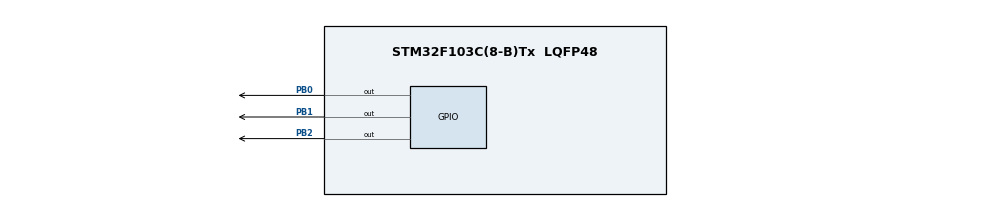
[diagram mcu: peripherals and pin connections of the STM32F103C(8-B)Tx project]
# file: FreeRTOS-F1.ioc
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FREERTOS.Tasks01=defaultTask,0,128,StartDefaultTask,Default;myTask01,-3,128,StartTask01,Default;myTask02,-3,128,StartTask02,Default
Mcu.Family=STM32F1
Mcu.Name=STM32F103C(8-B)Tx
Mcu.Package=LQFP48
NVIC.PriorityGroup=NVIC_PRIORITYGROUP_4
NVIC.TIM4_IRQn=true\:0\:0\:false\:false\:true\:false
NVIC.TimeBase=TIM4_IRQn
NVIC.TimeBaseIP=TIM4
PB0.Signal=GPIO_Output
PB1.Signal=GPIO_Output
PB2.Signal=GPIO_Output
ProjectManager.HeapSize=0x200
ProjectManager.StackSize=0x400
ProjectManager.TargetToolchain=MDK-ARM V4
RCC.APB1Freq_Value=8000000
RCC.APB2Freq_Value=8000000
VP_FREERTOS_VS_ENABLE.Mode=Enabled
VP_SYS_VS_ND.Mode=No_Debug
VP_SYS_VS_tim4.Mode=TIM4
board=FreeRTOS-F1

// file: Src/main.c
/**
  ******************************************************************************
  * File Name          : main.c
  * Description        : Main program body
  ******************************************************************************
  *
  * COPYRIGHT(c) 2016 STMicroelectronics
  *
  * Redistribution and use in source and binary forms, with or without modification,
  * are permitted provided that the following conditions are met:
  *   1. Redistributions of source code must retain the above copyright notice,
  *      this list of conditions and the following disclaimer.
  *   2. Redistributions in binary form must reproduce the above copyright notice,
  *      this list of conditions and the following disclaimer in the documentation
  *      and/or other materials provided with the distribution.
  *   3. Neither the name of STMicroelectronics nor the names of its contributors
  *      may be used to endorse or promote products derived from this software
  *      without specific prior written permission.
  *
  * THIS SOFTWARE IS PROVIDED BY THE COPYRIGHT HOLDERS AND CONTRIBUTORS "AS IS"
  * AND ANY EXPRESS OR IMPLIED WARRANTIES, INCLUDING, BUT NOT LIMITED TO, THE
  * IMPLIED WARRANTIES OF MERCHANTABILITY AND FITNESS FOR A PARTICULAR PURPOSE ARE
  * DISCLAIMED. IN NO EVENT SHALL THE COPYRIGHT HOLDER OR CONTRIBUTORS BE LIABLE
  * FOR ANY DIRECT, INDIRECT, INCIDENTAL, SPECIAL, EXEMPLARY, OR CONSEQUENTIAL
  * DAMAGES (INCLUDING, BUT NOT LIMITED TO, PROCUREMENT OF SUBSTITUTE GOODS OR
  * SERVICES; LOSS OF USE, DATA, OR PROFITS; OR BUSINESS INTERRUPTION) HOWEVER
  * CAUSED AND ON ANY THEORY OF LIABILITY, WHETHER IN CONTRACT, STRICT LIABILITY,
  * OR TORT (INCLUDING NEGLIGENCE OR OTHERWISE) ARISING IN ANY WAY OUT OF THE USE
  * OF THIS SOFTWARE, EVEN IF ADVISED OF THE POSSIBILITY OF SUCH DAMAGE.
  *
  ******************************************************************************
  */
#include "stm32f1xx_hal.h"
#include "cmsis_os.h"

osThreadId defaultTaskHandle;
osThreadId myTask01Handle;
osThreadId myTask02Handle;

/* USER CODE BEGIN PV */
/* Private variables ---------------------------------------------------------*/

/* USER CODE END PV */

void SystemClock_Config(void);
void Error_Handler(void);
static void MX_GPIO_Init(void);
void StartDefaultTask(void const * argument);
void StartTask01(void const * argument);
void StartTask02(void const * argument);

/* USER CODE BEGIN PFP */
/* Private function prototypes -----------------------------------------------*/

/* USER CODE END PFP */

int main(void)
{

  /* MCU Configuration----------------------------------------------------------*/

  /* Reset of all peripherals, Initializes the Flash interface and the Systick. */
  HAL_Init();

  /* Configure the system clock */
  SystemClock_Config();

  /* Initialize all configured peripherals */
  MX_GPIO_Init();

  /* Create the thread(s) */
  /* definition and creation of defaultTask */
  osThreadDef(defaultTask, StartDefaultTask, osPriorityNormal, 0, 128);
  defaultTaskHandle = osThreadCreate(osThread(defaultTask), NULL);

  /* definition and creation of myTask01 */
  osThreadDef(myTask01, StartTask01, osPriorityIdle, 0, 128);
  myTask01Handle = osThreadCreate(osThread(myTask01), NULL);

  /* definition and creation of myTask02 */
  osThreadDef(myTask02, StartTask02, osPriorityIdle, 0, 128);
  myTask02Handle = osThreadCreate(osThread(myTask02), NULL);

  /* Start scheduler */
  osKernelStart();

  /* We should never get here as control is now taken by the scheduler */

  /* Infinite loop */
  while (1)
  {

  }

}

/** System Clock Configuration
*/
void SystemClock_Config(void)
{

  RCC_OscInitTypeDef RCC_OscInitStruct;
  RCC_ClkInitTypeDef RCC_ClkInitStruct;

  RCC_OscInitStruct.OscillatorType = RCC_OSCILLATORTYPE_HSI;
  RCC_OscInitStruct.HSIState = RCC_HSI_ON;
  RCC_OscInitStruct.HSICalibrationValue = 16;
  RCC_OscInitStruct.PLL.PLLState = RCC_PLL_NONE;
  if (HAL_RCC_OscConfig(&RCC_OscInitStruct) != HAL_OK)
  {
    Error_Handler();
  }

  RCC_ClkInitStruct.ClockType = RCC_CLOCKTYPE_HCLK|RCC_CLOCKTYPE_SYSCLK
                              |RCC_CLOCKTYPE_PCLK1|RCC_CLOCKTYPE_PCLK2;
  RCC_ClkInitStruct.SYSCLKSource = RCC_SYSCLKSOURCE_HSI;
  RCC_ClkInitStruct.AHBCLKDivider = RCC_SYSCLK_DIV1;
  RCC_ClkInitStruct.APB1CLKDivider = RCC_HCLK_DIV1;
  RCC_ClkInitStruct.APB2CLKDivider = RCC_HCLK_DIV1;
  if (HAL_RCC_ClockConfig(&RCC_ClkInitStruct, FLASH_LATENCY_0) != HAL_OK)
  {
    Error_Handler();
  }

  HAL_SYSTICK_Config(HAL_RCC_GetHCLKFreq()/1000);

  HAL_SYSTICK_CLKSourceConfig(SYSTICK_CLKSOURCE_HCLK);

  /* SysTick_IRQn interrupt configuration */
  HAL_NVIC_SetPriority(SysTick_IRQn, 15, 0);
}

/** Configure pins as
        * Analog
        * Input
        * Output
        * EVENT_OUT
        * EXTI
        * Free pins are configured automatically as Analog (this feature is enabled through
        * the Code Generation settings)
*/
static void MX_GPIO_Init(void)
{

  GPIO_InitTypeDef GPIO_InitStruct;

  /* GPIO Ports Clock Enable */
  __HAL_RCC_GPIOC_CLK_ENABLE();
  __HAL_RCC_GPIOD_CLK_ENABLE();
  __HAL_RCC_GPIOA_CLK_ENABLE();
  __HAL_RCC_GPIOB_CLK_ENABLE();

  /*Configure GPIO pins : PC13 PC14 PC15 */
  GPIO_InitStruct.Pin = GPIO_PIN_13|GPIO_PIN_14|GPIO_PIN_15;
  GPIO_InitStruct.Mode = GPIO_MODE_ANALOG;
  HAL_GPIO_Init(GPIOC, &GPIO_InitStruct);

  /*Configure GPIO pins : PD0 PD1 */
  GPIO_InitStruct.Pin = GPIO_PIN_0|GPIO_PIN_1;
  GPIO_InitStruct.Mode = GPIO_MODE_ANALOG;
  HAL_GPIO_Init(GPIOD, &GPIO_InitStruct);

  /*Configure GPIO pins : PA0 PA1 PA2 PA3
                           PA4 PA5 PA6 PA7
                           PA8 PA9 PA10 PA11
                           PA12 PA13 PA14 PA15 */
  GPIO_InitStruct.Pin = GPIO_PIN_0|GPIO_PIN_1|GPIO_PIN_2|GPIO_PIN_3
                          |GPIO_PIN_4|GPIO_PIN_5|GPIO_PIN_6|GPIO_PIN_7
                          |GPIO_PIN_8|GPIO_PIN_9|GPIO_PIN_10|GPIO_PIN_11
                          |GPIO_PIN_12|GPIO_PIN_13|GPIO_PIN_14|GPIO_PIN_15;
  GPIO_InitStruct.Mode = GPIO_MODE_ANALOG;
  HAL_GPIO_Init(GPIOA, &GPIO_InitStruct);

  /*Configure GPIO pins : PB0 PB1 PB2 */
  GPIO_InitStruct.Pin = GPIO_PIN_0|GPIO_PIN_1|GPIO_PIN_2;
  GPIO_InitStruct.Mode = GPIO_MODE_OUTPUT_PP;
  GPIO_InitStruct.Speed = GPIO_SPEED_FREQ_LOW;
  HAL_GPIO_Init(GPIOB, &GPIO_InitStruct);

  /*Configure GPIO pins : PB10 PB11 PB12 PB13
                           PB14 PB15 PB3 PB4
                           PB5 PB6 PB7 PB8
                           PB9 */
  GPIO_InitStruct.Pin = GPIO_PIN_10|GPIO_PIN_11|GPIO_PIN_12|GPIO_PIN_13
                          |GPIO_PIN_14|GPIO_PIN_15|GPIO_PIN_3|GPIO_PIN_4
                          |GPIO_PIN_5|GPIO_PIN_6|GPIO_PIN_7|GPIO_PIN_8
                          |GPIO_PIN_9;
  GPIO_InitStruct.Mode = GPIO_MODE_ANALOG;
  HAL_GPIO_Init(GPIOB, &GPIO_InitStruct);

  /*Configure peripheral I/O remapping */
  __HAL_AFIO_REMAP_PD01_ENABLE();

  /*Configure GPIO pin Output Level */
  HAL_GPIO_WritePin(GPIOB, GPIO_PIN_0|GPIO_PIN_1|GPIO_PIN_2, GPIO_PIN_RESET);

}

/* StartDefaultTask function */
void StartDefaultTask(void const * argument)
{

  /* USER CODE BEGIN 5 */
  /* Infinite loop */
  for(;;)
  {
		HAL_GPIO_TogglePin(GPIOB, GPIO_PIN_1);
    osDelay(100);
  }
  /* USER CODE END 5 */
}

/* StartTask01 function */
void StartTask01(void const * argument)
{
  /* USER CODE BEGIN StartTask01 */
  /* Infinite loop */
  for(;;)
  {
		//Thuc hien blink LED noi voi chan PB0
		HAL_GPIO_TogglePin(GPIOB, GPIO_PIN_0);
    osDelay(1000);
  }
  /* USER CODE END StartTask01 */
}

/* StartTask02 function */
void StartTask02(void const * argument)
{
  /* USER CODE BEGIN StartTask02 */
  /* Infinite loop */
  for(;;)
  {
		HAL_GPIO_TogglePin(GPIOB, GPIO_PIN_2);
    osDelay(500);
  }
  /* USER CODE END StartTask02 */
}

void HAL_TIM_PeriodElapsedCallback(TIM_HandleTypeDef *htim)
{
  if (htim->Instance == TIM4) {
    HAL_IncTick();
  }
}

void Error_Handler(void)
{
  while(1)
  {
  }
}

/************************ (C) COPYRIGHT STMicroelectronics *****END OF FILE****/
